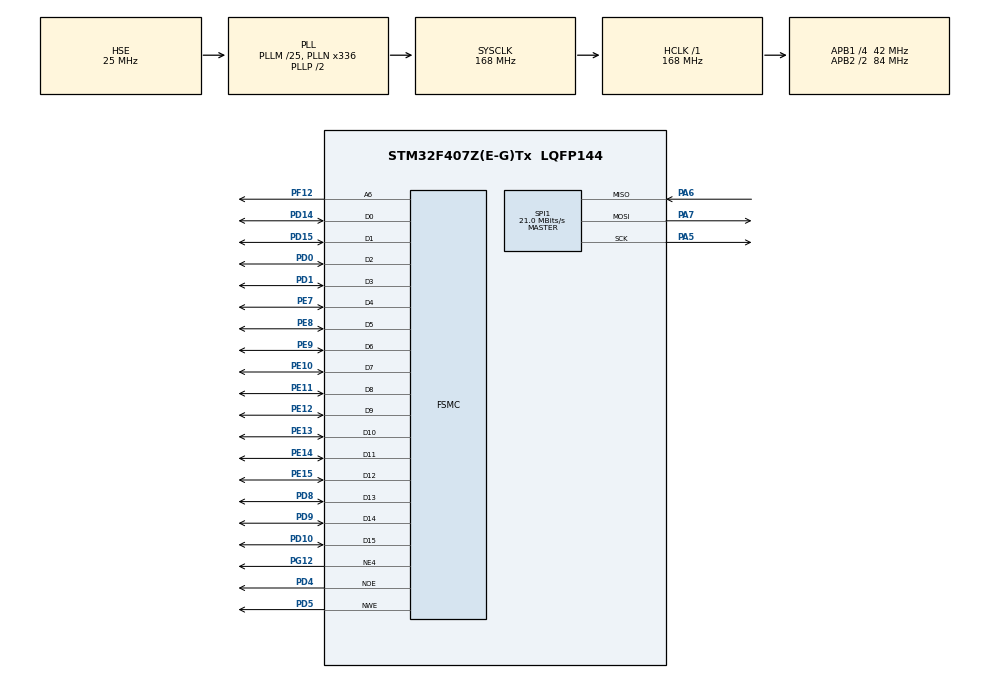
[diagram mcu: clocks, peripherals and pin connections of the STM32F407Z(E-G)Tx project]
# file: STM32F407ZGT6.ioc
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Mcu.Family=STM32F4
Mcu.Name=STM32F407Z(E-G)Tx
Mcu.Package=LQFP144
NVIC.PriorityGroup=NVIC_PRIORITYGROUP_4
PA13.Mode=Serial_Wire
PA13.Signal=SYS_JTMS-SWDIO
PA14.Mode=Serial_Wire
PA14.Signal=SYS_JTCK-SWCLK
PA5.Mode=Full_Duplex_Master
PA5.Signal=SPI1_SCK
PA6.Mode=Full_Duplex_Master
PA6.Signal=SPI1_MISO
PA7.Mode=Full_Duplex_Master
PA7.Signal=SPI1_MOSI
PD0.Signal=FSMC_D2_DA2
PD1.Signal=FSMC_D3_DA3
PD10.Signal=FSMC_D15_DA15
PD14.Signal=FSMC_D0_DA0
PD15.Signal=FSMC_D1_DA1
PD4.Signal=FSMC_NOE
PD5.Signal=FSMC_NWE
PD8.Signal=FSMC_D13_DA13
PD9.Signal=FSMC_D14_DA14
PE10.Signal=FSMC_D7_DA7
PE11.Signal=FSMC_D8_DA8
PE12.Signal=FSMC_D9_DA9
PE13.Signal=FSMC_D10_DA10
PE14.Signal=FSMC_D11_DA11
PE15.Signal=FSMC_D12_DA12
PE7.Signal=FSMC_D4_DA4
PE8.Signal=FSMC_D5_DA5
PE9.Signal=FSMC_D6_DA6
PF12.Signal=FSMC_A6
PG12.Mode=NorPsramChipSelect4_4
PG12.Signal=FSMC_NE4
PH0-OSC_IN.Mode=HSE-External-Oscillator
PH0-OSC_IN.Signal=RCC_OSC_IN
PH1-OSC_OUT.Mode=HSE-External-Oscillator
PH1-OSC_OUT.Signal=RCC_OSC_OUT
ProjectManager.HeapSize=0x200
ProjectManager.StackSize=0x400
ProjectManager.TargetToolchain=CMake
RCC.48MHZClocksFreq_Value=84000000
RCC.AHBFreq_Value=168000000
RCC.APB1CLKDivider=RCC_HCLK_DIV4
RCC.APB1Freq_Value=42000000
RCC.APB1TimFreq_Value=84000000
RCC.APB2CLKDivider=RCC_HCLK_DIV2
RCC.APB2Freq_Value=84000000
RCC.APB2TimFreq_Value=168000000
RCC.CortexFreq_Value=168000000
RCC.HCLKFreq_Value=168000000
RCC.HSE_VALUE=25000000
RCC.HSI_VALUE=16000000
RCC.LSE_VALUE=32768
RCC.PLLM=25
RCC.PLLN=336
RCC.PLLSourceVirtual=RCC_PLLSOURCE_HSE
RCC.SYSCLKFreq_VALUE=168000000
RCC.SYSCLKSource=RCC_SYSCLKSOURCE_PLLCLK
RCC.VCOOutputFreq_Value=336000000
SH.FSMC_A6.0=FSMC_A6,A6_4
SH.FSMC_D0_DA0.0=FSMC_D0,16b-d4
SH.FSMC_D10_DA10.0=FSMC_D10,16b-d4
SH.FSMC_D11_DA11.0=FSMC_D11,16b-d4
SH.FSMC_D12_DA12.0=FSMC_D12,16b-d4
SH.FSMC_D13_DA13.0=FSMC_D13,16b-d4
SH.FSMC_D14_DA14.0=FSMC_D14,16b-d4
SH.FSMC_D15_DA15.0=FSMC_D15,16b-d4
SH.FSMC_D1_DA1.0=FSMC_D1,16b-d4
SH.FSMC_D2_DA2.0=FSMC_D2,16b-d4
SH.FSMC_D3_DA3.0=FSMC_D3,16b-d4
SH.FSMC_D4_DA4.0=FSMC_D4,16b-d4
SH.FSMC_D5_DA5.0=FSMC_D5,16b-d4
SH.FSMC_D6_DA6.0=FSMC_D6,16b-d4
SH.FSMC_D7_DA7.0=FSMC_D7,16b-d4
SH.FSMC_D8_DA8.0=FSMC_D8,16b-d4
SH.FSMC_D9_DA9.0=FSMC_D9,16b-d4
SH.FSMC_NOE.0=FSMC_NOE,Lcd4
SH.FSMC_NWE.0=FSMC_NWE,Lcd4
SPI1.BaudRatePrescaler=SPI_BAUDRATEPRESCALER_4
SPI1.CalculateBaudRate=21.0 MBits/s
SPI1.Direction=SPI_DIRECTION_2LINES
SPI1.Mode=SPI_MODE_MASTER
SPI1.VirtualType=VM_MASTER
board=custom

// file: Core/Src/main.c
/* USER CODE BEGIN Header */
/**
  ******************************************************************************
  * @file           : main.c
  * @brief          : Main program body
  ******************************************************************************
  * @attention
  *
  * Copyright (c) 2026 STMicroelectronics.
  * All rights reserved.
  *
  * This software is licensed under terms that can be found in the LICENSE file
  * in the root directory of this software component.
  * If no LICENSE file comes with this software, it is provided AS-IS.
  *
  ******************************************************************************
  */
/* USER CODE END Header */
#include "main.h"

/* USER CODE BEGIN Includes */
#include <stdio.h>
#include "bsp_ili9341_lcd.h"
#include "stm32f4xx_hal_gpio.h"
#include "Measure.h"
/* USER CODE END Includes */

SPI_HandleTypeDef hspi1;

SRAM_HandleTypeDef hsram4;

void SystemClock_Config(void);
static void MX_GPIO_Init(void);
static void MX_FSMC_Init(void);
static void MX_SPI1_Init(void);

int main(void)
{

  /* MCU Configuration--------------------------------------------------------*/

  /* Reset of all peripherals, Initializes the Flash interface and the Systick. */
  HAL_Init();

  /* Configure the system clock */
  SystemClock_Config();

  /* Initialize all configured peripherals */
  MX_GPIO_Init();
  MX_FSMC_Init();
  MX_SPI1_Init();
  /* USER CODE BEGIN 2 */
  ILI9341_Init();

  ILI9341_DrawString(20, 20,  "ILI9341 Test",  COLOR_WHITE,  COLOR_BLACK, 2);
  ILI9341_DrawString(20, 50,  "STM32F407ZGT6", COLOR_YELLOW, COLOR_BLACK, 1);
  ILI9341_DrawString(20, 65,  "FSMC Bank4 OK", COLOR_GREEN,  COLOR_BLACK, 1);
  ILI9341_DrawString(20, 80, "Frequency Measurement:", COLOR_CYAN,   COLOR_BLACK, 2);
  /* USER CODE END 2 */

  /* Infinite loop */
  while (1)
  {

    /* USER CODE BEGIN 3 */
    char freq_text[32];
    double my_freq = Calculate_Frequency();
    snprintf(freq_text, sizeof(freq_text), "%.2f Hz", my_freq);
    ILI9341_DrawString(20, 110, freq_text, COLOR_MAGENTA, COLOR_BLACK, 2);
    HAL_Delay(1000);
  }
  /* USER CODE END 3 */
}

void SystemClock_Config(void)
{
  RCC_OscInitTypeDef RCC_OscInitStruct = {0};
  RCC_ClkInitTypeDef RCC_ClkInitStruct = {0};

  /** Configure the main internal regulator output voltage
  */
  __HAL_RCC_PWR_CLK_ENABLE();
  __HAL_PWR_VOLTAGESCALING_CONFIG(PWR_REGULATOR_VOLTAGE_SCALE1);

  /** Initializes the RCC Oscillators according to the specified parameters
  * in the RCC_OscInitTypeDef structure.
  */
  RCC_OscInitStruct.OscillatorType = RCC_OSCILLATORTYPE_HSE;
  RCC_OscInitStruct.HSEState = RCC_HSE_ON;
  RCC_OscInitStruct.PLL.PLLState = RCC_PLL_ON;
  RCC_OscInitStruct.PLL.PLLSource = RCC_PLLSOURCE_HSE;
  RCC_OscInitStruct.PLL.PLLM = 25;
  RCC_OscInitStruct.PLL.PLLN = 336;
  RCC_OscInitStruct.PLL.PLLP = RCC_PLLP_DIV2;
  RCC_OscInitStruct.PLL.PLLQ = 4;
  if (HAL_RCC_OscConfig(&RCC_OscInitStruct) != HAL_OK)
  {
    Error_Handler();
  }

  /** Initializes the CPU, AHB and APB buses clocks
  */
  RCC_ClkInitStruct.ClockType = RCC_CLOCKTYPE_HCLK|RCC_CLOCKTYPE_SYSCLK
                              |RCC_CLOCKTYPE_PCLK1|RCC_CLOCKTYPE_PCLK2;
  RCC_ClkInitStruct.SYSCLKSource = RCC_SYSCLKSOURCE_PLLCLK;
  RCC_ClkInitStruct.AHBCLKDivider = RCC_SYSCLK_DIV1;
  RCC_ClkInitStruct.APB1CLKDivider = RCC_HCLK_DIV4;
  RCC_ClkInitStruct.APB2CLKDivider = RCC_HCLK_DIV2;

  if (HAL_RCC_ClockConfig(&RCC_ClkInitStruct, FLASH_LATENCY_5) != HAL_OK)
  {
    Error_Handler();
  }
}

static void MX_SPI1_Init(void)
{

  /* SPI1 parameter configuration*/
  hspi1.Instance = SPI1;
  hspi1.Init.Mode = SPI_MODE_MASTER;
  hspi1.Init.Direction = SPI_DIRECTION_2LINES;
  hspi1.Init.DataSize = SPI_DATASIZE_8BIT;
  hspi1.Init.CLKPolarity = SPI_POLARITY_LOW;
  hspi1.Init.CLKPhase = SPI_PHASE_1EDGE;
  hspi1.Init.NSS = SPI_NSS_SOFT;
  hspi1.Init.BaudRatePrescaler = SPI_BAUDRATEPRESCALER_4;
  hspi1.Init.FirstBit = SPI_FIRSTBIT_MSB;
  hspi1.Init.TIMode = SPI_TIMODE_DISABLE;
  hspi1.Init.CRCCalculation = SPI_CRCCALCULATION_DISABLE;
  hspi1.Init.CRCPolynomial = 10;
  if (HAL_SPI_Init(&hspi1) != HAL_OK)
  {
    Error_Handler();
  }

}

static void MX_GPIO_Init(void)
{

  /* GPIO Ports Clock Enable */
  __HAL_RCC_GPIOH_CLK_ENABLE();
  __HAL_RCC_GPIOA_CLK_ENABLE();
  __HAL_RCC_GPIOF_CLK_ENABLE();
  __HAL_RCC_GPIOE_CLK_ENABLE();
  __HAL_RCC_GPIOD_CLK_ENABLE();
  __HAL_RCC_GPIOG_CLK_ENABLE();

}

/* FSMC initialization function */
static void MX_FSMC_Init(void)
{

  FSMC_NORSRAM_TimingTypeDef Timing = {0};

  /** Perform the SRAM4 memory initialization sequence
  */
  hsram4.Instance = FSMC_NORSRAM_DEVICE;
  hsram4.Extended = FSMC_NORSRAM_EXTENDED_DEVICE;
  /* hsram4.Init */
  hsram4.Init.NSBank = FSMC_NORSRAM_BANK4;
  hsram4.Init.DataAddressMux = FSMC_DATA_ADDRESS_MUX_DISABLE;
  hsram4.Init.MemoryType = FSMC_MEMORY_TYPE_SRAM;
  hsram4.Init.MemoryDataWidth = FSMC_NORSRAM_MEM_BUS_WIDTH_16;
  hsram4.Init.BurstAccessMode = FSMC_BURST_ACCESS_MODE_DISABLE;
  hsram4.Init.WaitSignalPolarity = FSMC_WAIT_SIGNAL_POLARITY_LOW;
  hsram4.Init.WrapMode = FSMC_WRAP_MODE_DISABLE;
  hsram4.Init.WaitSignalActive = FSMC_WAIT_TIMING_BEFORE_WS;
  hsram4.Init.WriteOperation = FSMC_WRITE_OPERATION_ENABLE;
  hsram4.Init.WaitSignal = FSMC_WAIT_SIGNAL_DISABLE;
  hsram4.Init.ExtendedMode = FSMC_EXTENDED_MODE_DISABLE;
  hsram4.Init.AsynchronousWait = FSMC_ASYNCHRONOUS_WAIT_DISABLE;
  hsram4.Init.WriteBurst = FSMC_WRITE_BURST_DISABLE;
  hsram4.Init.PageSize = FSMC_PAGE_SIZE_NONE;
  /* Timing */
  Timing.AddressSetupTime = 15;
  Timing.AddressHoldTime = 15;
  Timing.DataSetupTime = 255;
  Timing.BusTurnAroundDuration = 15;
  Timing.CLKDivision = 16;
  Timing.DataLatency = 17;
  Timing.AccessMode = FSMC_ACCESS_MODE_A;
  /* ExtTiming */

  if (HAL_SRAM_Init(&hsram4, &Timing, NULL) != HAL_OK)
  {
    Error_Handler( );
  }

}

void Error_Handler(void)
{
  __disable_irq();
  while (1)
  {
  }
}
